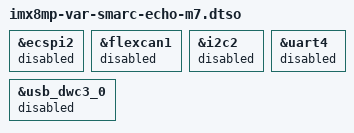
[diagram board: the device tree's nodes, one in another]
// SPDX-License-Identifier: (GPL-2.0+ OR MIT)
/*
 * Cortex-M7 support for Variscite VAR-SMARC-MX8M-PLUS on Echo-Board
 *
 * Link: https://variscite.com/carrier-boards/echo-board/
 *
 * Copyright (C) 2026 Variscite Ltd. - https://www.variscite.com/
 *
 */

/dts-v1/;
/plugin/;

#include "imx8mp-var-common-m7.dtsi"

/* Reserve the peripherals used by the Cortex-M7 firmware. */
&ecspi2 {
	status = "reserved";
};

&flexcan1 {
	status = "reserved";
};

&i2c2 {
	status = "reserved";
};

&uart4 {
	status = "reserved";
};

/* The USB-C role controller is on I2C2. */
&usb_dwc3_0 {
	status = "disabled";
};
